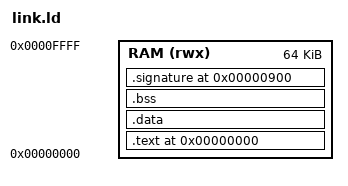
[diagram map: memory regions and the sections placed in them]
/* link.ld */
ENTRY(_start)

MEMORY
{
  RAM (rwx) : ORIGIN = 0x00000000, LENGTH = 64K
}

SECTIONS
{
  . = ORIGIN(RAM);

  .text : {
    *(.text.start)
    *(.text*)
    *(.rodata*)
  } > RAM

  .data : {
    *(.data*)
  } > RAM

  .bss : {
    __bss_start = .;
    *(.bss*)
    *(COMMON)
    __bss_end = .;
  } > RAM

  /* A fixed “signature” area the TB can check (matches your habit of using ~0x900). */
  . = 0x00000900;
  .signature : {
    __sig_start = .;
    *(.signature*)
    __sig_end = .;
  } > RAM

  _stack_top = ORIGIN(RAM) + LENGTH(RAM);
}
